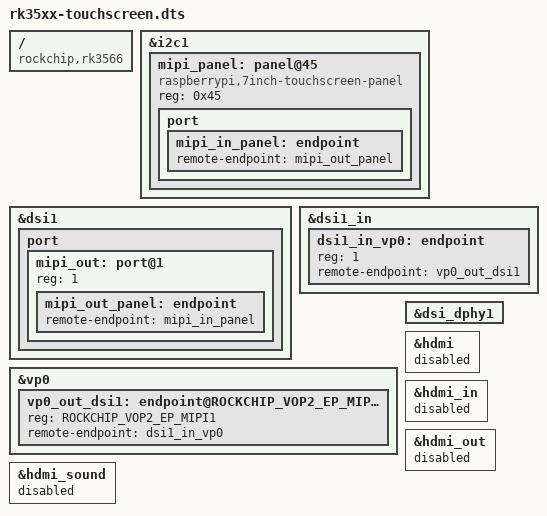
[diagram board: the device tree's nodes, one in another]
/dts-v1/;
/plugin/;

#include <dt-bindings/soc/rockchip,vop2.h>
#include <dt-bindings/clock/rk3568-cru.h>

/ {
	compatible = "rockchip,rk3566";

	fragment@0 {
		target = <&i2c1>;

		__overlay__ {
			status = "okay";

			/* panel-raspberrypi-touchscreen will attempt to read register 0x80 of the
			 * device at address 0x45 during rpi_touchscreen_probe(). */
			mipi_panel: panel@45 {
				compatible = "raspberrypi,7inch-touchscreen-panel";
				reg = <0x45>;
				status = "okay";

				port {
					mipi_in_panel: endpoint {
						remote-endpoint = <&mipi_out_panel>;
					};
				};
			};
		};
	};

	fragment@1 {
		target = <&dsi1>;

		__overlay__ {
			status = "okay";

			port {              
				mipi_out: port@1 {
					reg = <1>;

					mipi_out_panel: endpoint {
						remote-endpoint = <&mipi_in_panel>;
					};
				};
			};
		};
	};

	fragment@2 {
		target = <&dsi1_in>;

		__overlay__ {
			dsi1_in_vp0: endpoint {
				reg = <1>;
				remote-endpoint = <&vp0_out_dsi1>;
			};
		};
	};

	fragment@3 {
		target = <&vp0>;

		__overlay__ {
			vp0_out_dsi1: endpoint@ROCKCHIP_VOP2_EP_MIPI1 {
				reg = <ROCKCHIP_VOP2_EP_MIPI1>;
				remote-endpoint = <&dsi1_in_vp0>;
			};
		};
	};

	fragment@4 {
		target = <&dsi_dphy1>;

		__overlay__ {
			status = "okay";
		};
	};

	/* Disable all HDMI things. */
	fragment@5 {
		target = <&hdmi>;

		__overlay__ {
			status = "disabled";
		};
	};

	fragment@6 {
		target = <&hdmi_in>;

		__overlay__ {
			status = "disabled";
		};
	};

	fragment@7 {
		target = <&hdmi_out>;

		__overlay__ {
			status = "disabled";
		};
	};

	fragment@8 {
		target = <&hdmi_sound>;

		__overlay__ {
			status = "disabled";
		};
	};
};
